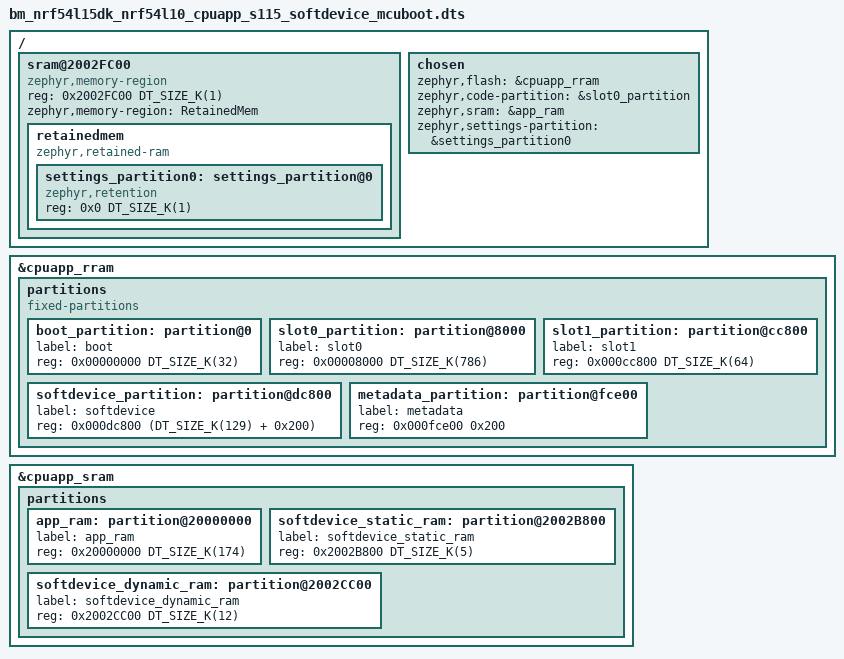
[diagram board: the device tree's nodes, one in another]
/*
 * Copyright (c) 2025 Nordic Semiconductor ASA
 *
 * SPDX-License-Identifier: LicenseRef-Nordic-5-Clause
 */

/dts-v1/;

#include <nordic/nrf54l10_cpuapp.dtsi>
#include "bm_nrf54l15dk_nrf54l10_cpuapp_common.dtsi"

/ {
	sram@2002FC00 {
		compatible = "zephyr,memory-region", "mmio-sram";
		reg = <0x2002FC00 DT_SIZE_K(1)>;
		zephyr,memory-region = "RetainedMem";
		status = "okay";

		retainedmem {
			compatible = "zephyr,retained-ram";
			status = "okay";
			#address-cells = <1>;
			#size-cells = <1>;

			settings_partition0: settings_partition@0 {
				compatible = "zephyr,retention";
				status = "okay";
				reg = <0x0 DT_SIZE_K(1)>;
			};
		};
	};

	chosen {
		zephyr,flash = &cpuapp_rram;
		zephyr,code-partition = &slot0_partition;
		zephyr,sram = &app_ram;
		zephyr,settings-partition = &settings_partition0;
	};
};

&cpuapp_rram {
	status = "okay";

	partitions {
		compatible = "fixed-partitions";
		#address-cells = <1>;
		#size-cells = <1>;

		boot_partition: partition@0 {
			label = "boot";
			reg = <0x00000000 DT_SIZE_K(32)>;
		};

		slot0_partition: partition@8000 {
			label = "slot0";
			reg = <0x00008000 DT_SIZE_K(786)>;
		};

		slot1_partition: partition@cc800 {
			label = "slot1";
			reg = <0x000cc800 DT_SIZE_K(64)>;
		};

		softdevice_partition: partition@dc800 {
			label = "softdevice";
			reg = <0x000dc800 (DT_SIZE_K(129) + 0x200)>;
		};

		metadata_partition: partition@fce00 {
			label = "metadata";
			reg = <0x000fce00 0x200>;
		};
	};
};

&cpuapp_sram {
	status = "okay";

	partitions {
		#address-cells = <1>;
		#size-cells = <1>;

		app_ram: partition@20000000 {
			label = "app_ram";
			reg = <0x20000000 DT_SIZE_K(174)>;
		};

		softdevice_static_ram: partition@2002B800 {
			label = "softdevice_static_ram";
			reg = <0x2002B800 DT_SIZE_K(5)>;
		};

		softdevice_dynamic_ram: partition@2002CC00 {
			label = "softdevice_dynamic_ram";
			reg = <0x2002CC00 DT_SIZE_K(12)>;
		};
	};
};
